VERSION ""

NS_ :

BS_:

BU_:

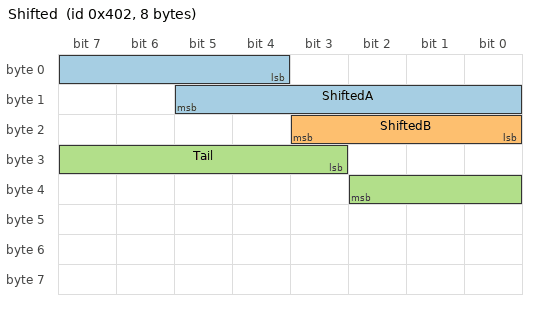
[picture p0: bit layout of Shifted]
BO_ 1026 Shifted: 8 Vector__XXX
 SG_ ShiftedA : 4|10@1+ (1,0) [0|0] "" Vector__XXX
 SG_ ShiftedB : 19|4@0+ (1,0) [0|0] "" Vector__XXX
 SG_ Tail : 27|8@1+ (1,0) [0|0] "" Vector__XXX
